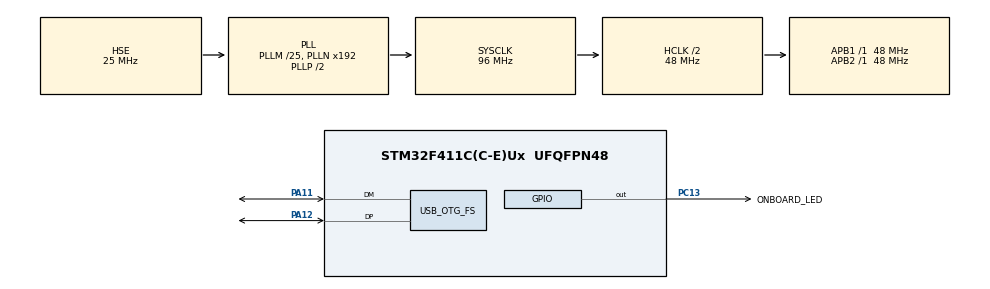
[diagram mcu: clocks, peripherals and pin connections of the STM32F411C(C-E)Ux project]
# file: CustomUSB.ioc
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Mcu.Family=STM32F4
Mcu.Name=STM32F411C(C-E)Ux
Mcu.Package=UFQFPN48
NVIC.OTG_FS_IRQn=true\:0\:0\:false\:false\:true\:true\:true\:true
NVIC.PriorityGroup=NVIC_PRIORITYGROUP_4
PA11.Mode=Device_Only
PA11.Signal=USB_OTG_FS_DM
PA12.Mode=Device_Only
PA12.Signal=USB_OTG_FS_DP
PC13-ANTI_TAMP.GPIO_Label=ONBOARD_LED
PC13-ANTI_TAMP.Signal=GPIO_Output
PH0\ -\ OSC_IN.Mode=HSE-External-Oscillator
PH0\ -\ OSC_IN.Signal=RCC_OSC_IN
PH1\ -\ OSC_OUT.Mode=HSE-External-Oscillator
PH1\ -\ OSC_OUT.Signal=RCC_OSC_OUT
ProjectManager.HeapSize=0x200
ProjectManager.StackSize=0x400
ProjectManager.TargetToolchain=STM32CubeIDE
RCC.48MHZClocksFreq_Value=48000000
RCC.AHBCLKDivider=RCC_SYSCLK_DIV2
RCC.AHBFreq_Value=48000000
RCC.APB1Freq_Value=48000000
RCC.APB1TimFreq_Value=48000000
RCC.APB2Freq_Value=48000000
RCC.APB2TimFreq_Value=48000000
RCC.CortexFreq_Value=48000000
RCC.HCLKFreq_Value=48000000
RCC.HSE_VALUE=25000000
RCC.HSI_VALUE=16000000
RCC.LSE_VALUE=32768
RCC.PLLM=25
RCC.SYSCLKFreq_VALUE=96000000
RCC.SYSCLKSource=RCC_SYSCLKSOURCE_PLLCLK
RCC.VCOOutputFreq_Value=192000000
USB_DEVICE.CLASS_NAME_FS=CUSTOM_HID
USB_DEVICE.CUSTOM_HID_FS_BINTERVAL=0xA
USB_DEVICE.MANUFACTURER_STRING=Theo&STMicroelectronics
USB_DEVICE.VirtualMode=CustomHid
USB_DEVICE.VirtualModeFS=Custom_Hid_FS
USB_OTG_FS.VirtualMode=Device_Only
VP_USB_DEVICE_VS_USB_DEVICE_CUSTOM_HID_FS.Mode=CUSTOM_HID_FS
board=custom

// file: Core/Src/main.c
/* USER CODE BEGIN Header */
/**
 ******************************************************************************
 * @file           : main.c
 * @brief          : Main program body
 ******************************************************************************
 * @attention
 *
 * Copyright (c) 2025 STMicroelectronics.
 * All rights reserved.
 *
 * This software is licensed under terms that can be found in the LICENSE file
 * in the root directory of this software component.
 * If no LICENSE file comes with this software, it is provided AS-IS.
 *
 ******************************************************************************
 */
/* USER CODE END Header */
#include "main.h"
#include "usb_device.h"
#include "usbd_custom_hid_if.h"
#include "keycodes.h"

void SystemClock_Config(void);
static void MX_GPIO_Init(void);

int main(void) {

	/* MCU Configuration--------------------------------------------------------*/

	/* Reset of all peripherals, Initializes the Flash interface and the Systick. */
	HAL_Init();

	/* Configure the system clock */
	SystemClock_Config();

	/* Initialize all configured peripherals */
	MX_GPIO_Init();
	MX_USB_DEVICE_Init();
	/* USER CODE BEGIN 2 */

	typedef struct {
		uint8_t modifier;   // Modifier keys (Shift, Ctrl, Alt, etc.)
		uint8_t reserved;   // Reserved (usually 0)
		uint8_t keycode[6]; // Up to 6 keycodes can be sent simultaneously
	} keyboard_report_t;

	// Function to send a key
	void send_key(uint8_t key) {
		keyboard_report_t keyboard_report;

		keyboard_report.modifier = 0;       // No modifier keys
		keyboard_report.reserved = 0;       // Reserved
		keyboard_report.keycode[0] = key;    // The key to send
		keyboard_report.keycode[1] = 0;    // Release other keys
		keyboard_report.keycode[2] = 0;
		keyboard_report.keycode[3] = 0;
		keyboard_report.keycode[4] = 0;
		keyboard_report.keycode[5] = 0;

		USBD_CUSTOM_HID_SendReport_FS((uint8_t*) &keyboard_report,
				sizeof(keyboard_report));
		HAL_Delay(100); // Add a small delay

		// Release the key (send a report with all keycodes set to 0)
		keyboard_report.keycode[0] = 0;
		USBD_CUSTOM_HID_SendReport_FS((uint8_t*) &keyboard_report,
				sizeof(keyboard_report));
		HAL_Delay(100); // Add a small delay
	}

	/* USER CODE END 2 */

	/* Infinite loop */
	while (1) {

		/* USER CODE BEGIN 3 */
		HAL_GPIO_TogglePin(ONBOARD_LED_GPIO_Port, ONBOARD_LED_Pin);
		send_key(KEY_F);
		send_key(KEY_U);
		send_key(KEY_C);
		send_key(KEY_K);
		send_key(KEY_SPACE);
		send_key(KEY_Y);
		send_key(KEY_E);
		send_key(KEY_A);
		send_key(KEY_SPACE);
		HAL_Delay(1000);
	}
	/* USER CODE END 3 */
}

void SystemClock_Config(void) {
	RCC_OscInitTypeDef RCC_OscInitStruct = { 0 };
	RCC_ClkInitTypeDef RCC_ClkInitStruct = { 0 };

	/** Configure the main internal regulator output voltage
	 */
	__HAL_RCC_PWR_CLK_ENABLE();
	__HAL_PWR_VOLTAGESCALING_CONFIG(PWR_REGULATOR_VOLTAGE_SCALE1);

	/** Initializes the RCC Oscillators according to the specified parameters
	 * in the RCC_OscInitTypeDef structure.
	 */
	RCC_OscInitStruct.OscillatorType = RCC_OSCILLATORTYPE_HSE;
	RCC_OscInitStruct.HSEState = RCC_HSE_ON;
	RCC_OscInitStruct.PLL.PLLState = RCC_PLL_ON;
	RCC_OscInitStruct.PLL.PLLSource = RCC_PLLSOURCE_HSE;
	RCC_OscInitStruct.PLL.PLLM = 25;
	RCC_OscInitStruct.PLL.PLLN = 192;
	RCC_OscInitStruct.PLL.PLLP = RCC_PLLP_DIV2;
	RCC_OscInitStruct.PLL.PLLQ = 4;
	if (HAL_RCC_OscConfig(&RCC_OscInitStruct) != HAL_OK) {
		Error_Handler();
	}

	/** Initializes the CPU, AHB and APB buses clocks
	 */
	RCC_ClkInitStruct.ClockType = RCC_CLOCKTYPE_HCLK | RCC_CLOCKTYPE_SYSCLK
			| RCC_CLOCKTYPE_PCLK1 | RCC_CLOCKTYPE_PCLK2;
	RCC_ClkInitStruct.SYSCLKSource = RCC_SYSCLKSOURCE_PLLCLK;
	RCC_ClkInitStruct.AHBCLKDivider = RCC_SYSCLK_DIV2;
	RCC_ClkInitStruct.APB1CLKDivider = RCC_HCLK_DIV1;
	RCC_ClkInitStruct.APB2CLKDivider = RCC_HCLK_DIV1;

	if (HAL_RCC_ClockConfig(&RCC_ClkInitStruct, FLASH_LATENCY_1) != HAL_OK) {
		Error_Handler();
	}
}

static void MX_GPIO_Init(void) {
	GPIO_InitTypeDef GPIO_InitStruct = { 0 };

	/* GPIO Ports Clock Enable */
	__HAL_RCC_GPIOC_CLK_ENABLE();
	__HAL_RCC_GPIOH_CLK_ENABLE();
	__HAL_RCC_GPIOA_CLK_ENABLE();

	/*Configure GPIO pin Output Level */
	HAL_GPIO_WritePin(ONBOARD_LED_GPIO_Port, ONBOARD_LED_Pin, GPIO_PIN_RESET);

	/*Configure GPIO pin : ONBOARD_LED_Pin */
	GPIO_InitStruct.Pin = ONBOARD_LED_Pin;
	GPIO_InitStruct.Mode = GPIO_MODE_OUTPUT_PP;
	GPIO_InitStruct.Pull = GPIO_NOPULL;
	GPIO_InitStruct.Speed = GPIO_SPEED_FREQ_LOW;
	HAL_GPIO_Init(ONBOARD_LED_GPIO_Port, &GPIO_InitStruct);

}

void Error_Handler(void) {
	__disable_irq();
	while (1) {
	}
}
